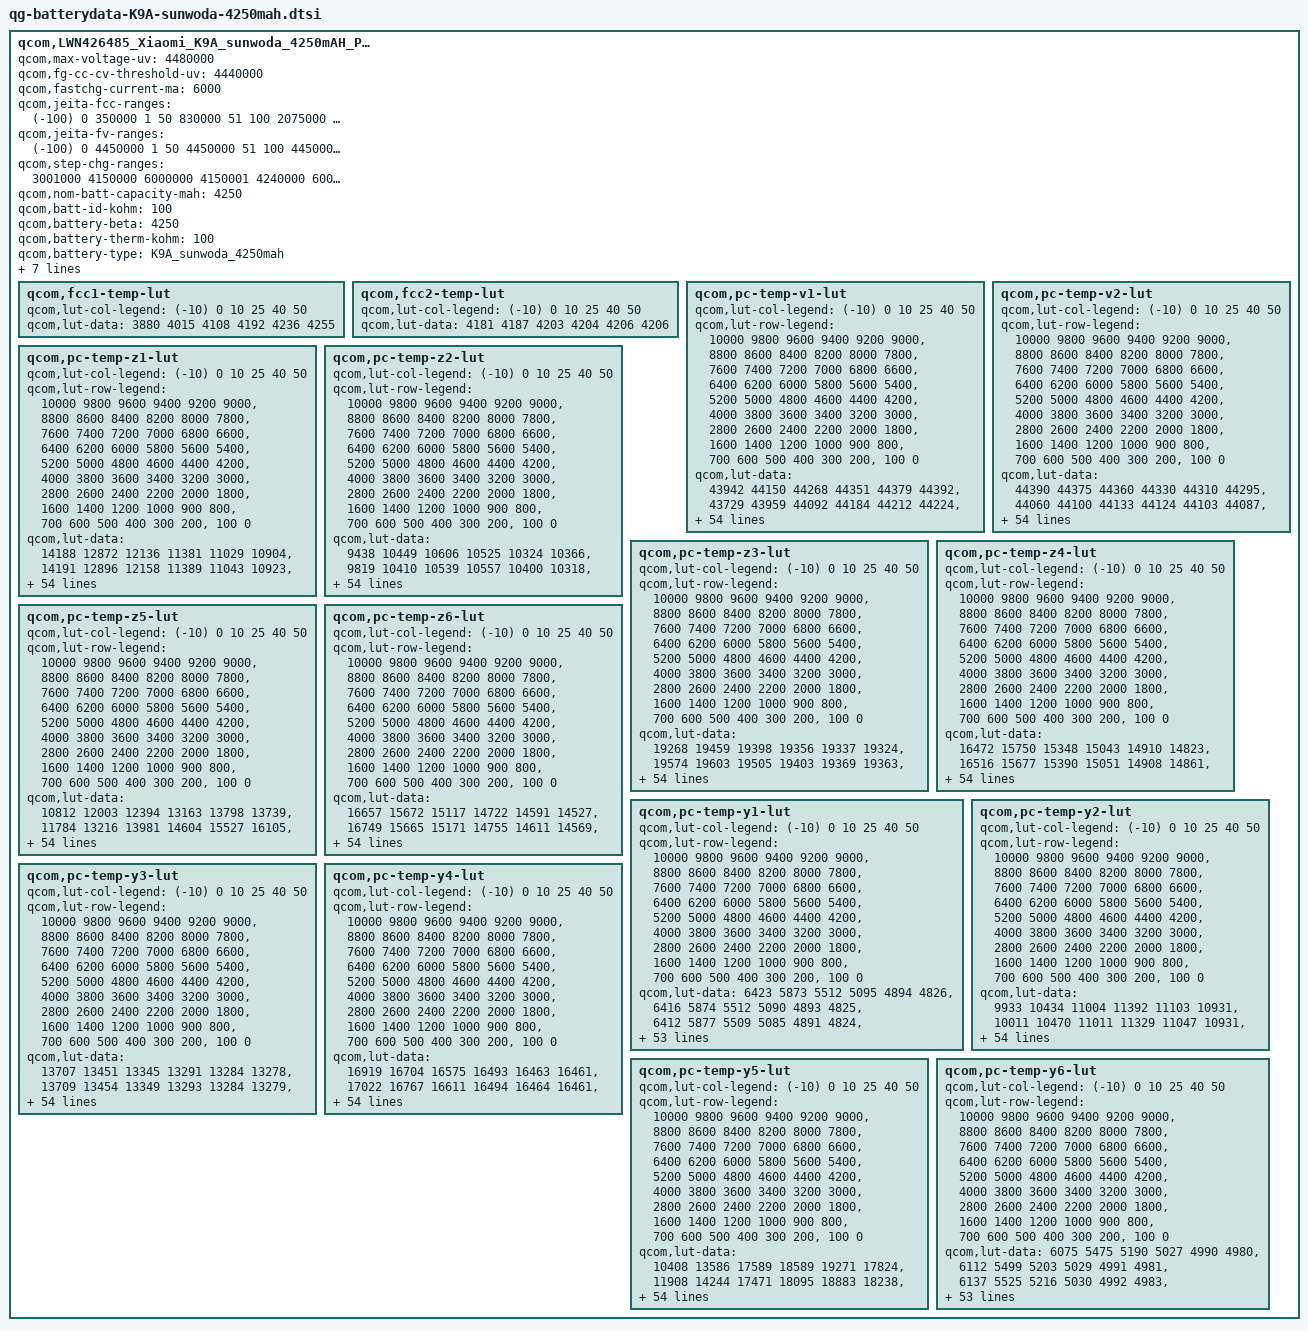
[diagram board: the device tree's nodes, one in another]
qcom,LWN426485_Xiaomi_K9A_sunwoda_4250mAH_PM7150 {
	/* LWN426485_Xiaomi_K9A_sunwoda_4250mAH_PM7150_averaged_MasterSlave_Sep23th2020 */
	qcom,max-voltage-uv = <4480000>;
	qcom,fg-cc-cv-threshold-uv = <4440000>;
	qcom,fastchg-current-ma = <6000>;
	qcom,jeita-fcc-ranges = <(-100)  0   350000
				1  50  830000
				51  100  2075000
				101 150  3320000
				151 480  6000000
				481 600  2075000>;
	qcom,jeita-fv-ranges = <(-100)  0   4450000
				1   50  4450000
				51  100  4450000
				101 150  4450000
				151 480  4480000
				481 600  4100000>;
	qcom,step-chg-ranges = <3001000  4150000  6000000
				4150001  4240000  6000000
				4240001  4350000  5400000
				4350001  4400000  5400000
				4400001  4440000  5400000
				4440001  4480000  3320000>;

	qcom,nom-batt-capacity-mah = <4250>;
	qcom,batt-id-kohm = <100>;
	qcom,battery-beta = <4250>;
	qcom,battery-therm-kohm = <100>;
	qcom,battery-type = "K9A_sunwoda_4250mah";
	qcom,qg-batt-profile-ver = <100>;
	qcom,taper-fcc;

	mi,six-pin-battery;
	mi,use-bq-pump;
	mi,step-chg-hysteresis = <5000>;
	mi-ffc-current-cfg = <350 870000 870000 (-550) (-600)>;	/* specification 100% current: 849mA */

	qcom,fcc1-temp-lut {
		qcom,lut-col-legend = <(-10) 0 10 25 40 50>;
		qcom,lut-data = <3880 4015 4108 4192 4236 4255>;
	};

	qcom,fcc2-temp-lut {
		qcom,lut-col-legend = <(-10) 0 10 25 40 50>;
		qcom,lut-data = <4181 4187 4203 4204 4206 4206>;
	};

	qcom,pc-temp-v1-lut {
		qcom,lut-col-legend = <(-10) 0 10 25 40 50>;
		qcom,lut-row-legend = <10000 9800 9600 9400 9200 9000>,
			<8800 8600 8400 8200 8000 7800>,
			<7600 7400 7200 7000 6800 6600>,
			<6400 6200 6000 5800 5600 5400>,
			<5200 5000 4800 4600 4400 4200>,
			<4000 3800 3600 3400 3200 3000>,
			<2800 2600 2400 2200 2000 1800>,
			<1600 1400 1200 1000 900 800>,
			<700 600 500 400 300 200>,
			<100 0>;
		qcom,lut-data = <43942 44150 44268 44351 44379 44392>,
			<43729 43959 44092 44184 44212 44224>,
			<43494 43756 43902 44006 44036 44051>,
			<43254 43541 43702 43817 43851 43868>,
			<43019 43311 43488 43618 43657 43674>,
			<42783 43076 43259 43405 43451 43469>,
			<42548 42838 43024 43176 43229 43250>,
			<42312 42596 42783 42939 42995 43020>,
			<42078 42357 42537 42696 42756 42783>,
			<41851 42119 42294 42448 42508 42538>,
			<41633 41884 42053 42203 42261 42291>,
			<41422 41655 41816 41962 42017 42046>,
			<41214 41430 41585 41723 41775 41802>,
			<41012 41212 41357 41487 41538 41563>,
			<40811 41003 41139 41256 41306 41331>,
			<40604 40800 40930 41033 41080 41104>,
			<40390 40593 40728 40818 40860 40883>,
			<40191 40381 40528 40610 40647 40667>,
			<40017 40176 40336 40418 40446 40463>,
			<39858 39993 40129 40232 40260 40275>,
			<39702 39827 39876 40012 40054 40074>,
			<39545 39642 39611 39721 39792 39822>,
			<39391 39392 39386 39448 39520 39551>,
			<39236 39134 39185 39264 39316 39338>,
			<39075 38961 39023 39116 39152 39165>,
			<38927 38840 38912 38985 39006 39014>,
			<38813 38745 38826 38865 38872 38878>,
			<38717 38674 38740 38756 38751 38756>,
			<38639 38617 38651 38650 38639 38644>,
			<38577 38561 38565 38547 38536 38540>,
			<38527 38503 38486 38456 38442 38445>,
			<38480 38446 38411 38377 38354 38356>,
			<38435 38393 38345 38305 38274 38274>,
			<38394 38342 38289 38240 38201 38196>,
			<38355 38295 38240 38182 38134 38123>,
			<38321 38254 38195 38126 38068 38049>,
			<38282 38216 38156 38076 38005 37972>,
			<38227 38165 38109 38024 37939 37890>,
			<38149 38083 38031 37951 37857 37797>,
			<38060 37979 37926 37851 37755 37688>,
			<37962 37862 37810 37737 37640 37569>,
			<37846 37722 37678 37611 37509 37435>,
			<37691 37566 37528 37469 37365 37290>,
			<37512 37399 37350 37300 37198 37124>,
			<37355 37297 37215 37164 37079 37013>,
			<37264 37213 37137 37085 37011 36951>,
			<37230 37182 37117 37066 36991 36935>,
			<37201 37155 37096 37047 36979 36918>,
			<37158 37116 37078 37022 36948 36882>,
			<36999 36983 36951 36924 36800 36696>,
			<36630 36611 36571 36584 36428 36323>,
			<36127 36111 36083 36113 35954 35844>,
			<35488 35473 35452 35506 35337 35219>,
			<34607 34594 34580 34673 34495 34363>,
			<33175 33168 33174 33368 33174 33011>,
			<30000 30000 30000 30000 30000 30000>;
	};

	qcom,pc-temp-v2-lut {
		qcom,lut-col-legend = <(-10) 0 10 25 40 50>;
		qcom,lut-row-legend = <10000 9800 9600 9400 9200 9000>,
			<8800 8600 8400 8200 8000 7800>,
			<7600 7400 7200 7000 6800 6600>,
			<6400 6200 6000 5800 5600 5400>,
			<5200 5000 4800 4600 4400 4200>,
			<4000 3800 3600 3400 3200 3000>,
			<2800 2600 2400 2200 2000 1800>,
			<1600 1400 1200 1000 900 800>,
			<700 600 500 400 300 200>,
			<100 0>;
		qcom,lut-data = <44390 44375 44360 44330 44310 44295>,
			<44060 44100 44133 44124 44103 44087>,
			<43758 43844 43912 43918 43896 43880>,
			<43488 43612 43699 43714 43690 43675>,
			<43253 43405 43496 43512 43487 43473>,
			<43019 43193 43286 43302 43277 43264>,
			<42762 42953 43053 43074 43050 43037>,
			<42498 42698 42809 42833 42812 42801>,
			<42260 42442 42562 42591 42572 42561>,
			<42052 42179 42313 42344 42327 42317>,
			<41839 41926 42064 42098 42082 42073>,
			<41579 41697 41819 41856 41840 41832>,
			<41298 41481 41576 41616 41600 41593>,
			<41081 41267 41340 41380 41365 41358>,
			<40941 41052 41109 41150 41137 41128>,
			<40788 40836 40887 40924 40914 40904>,
			<40492 40615 40688 40708 40697 40689>,
			<40055 40390 40499 40497 40486 40481>,
			<39696 40144 40278 40285 40281 40279>,
			<39439 39856 40001 40072 40088 40089>,
			<39213 39569 39721 39851 39886 39889>,
			<38989 39326 39477 39597 39635 39639>,
			<38772 39106 39252 39322 39353 39357>,
			<38592 38910 39058 39104 39129 39134>,
			<38442 38736 38891 38937 38961 38968>,
			<38320 38575 38741 38794 38816 38824>,
			<38234 38403 38604 38664 38685 38692>,
			<38170 38222 38479 38547 38567 38572>,
			<38112 38098 38365 38437 38458 38462>,
			<38059 38029 38263 38332 38357 38362>,
			<38008 37978 38168 38235 38265 38269>,
			<37954 37934 38070 38146 38180 38183>,
			<37896 37898 37971 38067 38103 38104>,
			<37837 37859 37891 37990 38022 38019>,
			<37779 37814 37833 37919 37935 37922>,
			<37720 37764 37783 37848 37842 37819>,
			<37653 37707 37734 37762 37742 37708>,
			<37577 37641 37689 37662 37631 37590>,
			<37494 37564 37631 37563 37525 37478>,
			<37396 37468 37541 37470 37432 37381>,
			<37289 37356 37428 37373 37337 37285>,
			<37189 37238 37301 37254 37220 37164>,
			<37095 37109 37155 37114 37083 37024>,
			<37011 37001 37031 36994 36961 36901>,
			<36938 36914 36931 36909 36873 36816>,
			<36860 36815 36858 36881 36843 36793>,
			<36813 36753 36821 36861 36832 36782>,
			<36756 36665 36777 36829 36813 36762>,
			<36675 36557 36688 36750 36761 36695>,
			<36526 36407 36503 36437 36543 36427>,
			<36243 36143 36163 35965 36114 35989>,
			<35774 35679 35613 35351 35569 35430>,
			<35096 35018 34876 34538 34860 34697>,
			<34143 34068 33875 33341 33863 33683>,
			<32437 32333 32156 31825 32358 32154>,
			<27192 27175 27324 29658 28869 28231>;
	};

	qcom,pc-temp-z1-lut {
		qcom,lut-col-legend = <(-10) 0 10 25 40 50>;
		qcom,lut-row-legend = <10000 9800 9600 9400 9200 9000>,
			<8800 8600 8400 8200 8000 7800>,
			<7600 7400 7200 7000 6800 6600>,
			<6400 6200 6000 5800 5600 5400>,
			<5200 5000 4800 4600 4400 4200>,
			<4000 3800 3600 3400 3200 3000>,
			<2800 2600 2400 2200 2000 1800>,
			<1600 1400 1200 1000 900 800>,
			<700 600 500 400 300 200>,
			<100 0>;
		qcom,lut-data = <14188 12872 12136 11381 11029 10904>,
			<14191 12896 12158 11389 11043 10923>,
			<14176 12910 12148 11392 11050 10934>,
			<14160 12910 12132 11387 11050 10936>,
			<14156 12902 12118 11377 11044 10934>,
			<14152 12891 12094 11367 11038 10931>,
			<14147 12878 12070 11355 11033 10928>,
			<14131 12861 12051 11343 11028 10924>,
			<14103 12844 12032 11333 11024 10922>,
			<14089 12823 12016 11323 11021 10919>,
			<14106 12802 12001 11318 11019 10918>,
			<14133 12785 11990 11314 11016 10916>,
			<14140 12771 11985 11312 11013 10915>,
			<14128 12757 11982 11309 11011 10914>,
			<14111 12736 11978 11307 11010 10913>,
			<14104 12713 11969 11306 11009 10913>,
			<14106 12698 11959 11305 11009 10913>,
			<14107 12686 11955 11305 11009 10914>,
			<14097 12680 11952 11306 11010 10914>,
			<14082 12680 11951 11307 11010 10915>,
			<14079 12680 11952 11308 11010 10916>,
			<14076 12681 11954 11309 11010 10917>,
			<14072 12682 11956 11310 11011 10917>,
			<14074 12684 11960 11312 11012 10918>,
			<14099 12688 11963 11316 11014 10920>,
			<14127 12697 11966 11321 11017 10922>,
			<14134 12706 11969 11325 11020 10924>,
			<14121 12708 11972 11331 11023 10927>,
			<14110 12708 11978 11335 11026 10930>,
			<14105 12708 11983 11340 11029 10933>,
			<14099 12708 11984 11344 11031 10935>,
			<14099 12709 11984 11348 11035 10938>,
			<14100 12714 11985 11352 11038 10940>,
			<14099 12724 11994 11356 11042 10943>,
			<14097 12731 12006 11360 11045 10946>,
			<14093 12733 12013 11365 11049 10950>,
			<14087 12730 12018 11370 11052 10953>,
			<14080 12731 12022 11376 11056 10956>,
			<14071 12739 12029 11383 11059 10958>,
			<14067 12750 12041 11391 11063 10961>,
			<14067 12764 12049 11399 11066 10964>,
			<14067 12784 12060 11405 11070 10967>,
			<14075 12792 12069 11411 11073 10969>,
			<14085 12794 12077 11421 11076 10970>,
			<14057 12817 12089 11434 11081 10973>,
			<14100 12778 12085 11445 11084 10975>,
			<14047 12790 12089 11442 11082 10975>,
			<14105 12787 12081 11444 11084 10976>,
			<14140 12786 12081 11448 11085 10977>,
			<14142 12817 12096 11461 11091 10982>,
			<14115 12800 12120 11469 11096 10985>,
			<14104 12831 12124 11478 11103 10990>,
			<14143 12849 12145 11494 11112 10998>,
			<14151 12883 12191 11506 11122 11009>,
			<14151 12883 12191 11506 11122 11009>,
			<14151 12883 12191 11506 11122 11009>;
	};

	qcom,pc-temp-z2-lut {
		qcom,lut-col-legend = <(-10) 0 10 25 40 50>;
		qcom,lut-row-legend = <10000 9800 9600 9400 9200 9000>,
			<8800 8600 8400 8200 8000 7800>,
			<7600 7400 7200 7000 6800 6600>,
			<6400 6200 6000 5800 5600 5400>,
			<5200 5000 4800 4600 4400 4200>,
			<4000 3800 3600 3400 3200 3000>,
			<2800 2600 2400 2200 2000 1800>,
			<1600 1400 1200 1000 900 800>,
			<700 600 500 400 300 200>,
			<100 0>;
		qcom,lut-data = <9438 10449 10606 10525 10324 10366>,
			<9819 10410 10539 10557 10400 10318>,
			<10009 10371 10502 10567 10444 10314>,
			<10182 10331 10462 10554 10445 10318>,
			<10179 10284 10422 10525 10425 10348>,
			<10152 10244 10379 10490 10403 10364>,
			<10131 10216 10343 10438 10359 10316>,
			<10119 10194 10314 10402 10311 10235>,
			<10109 10183 10292 10386 10297 10193>,
			<10106 10175 10286 10376 10294 10170>,
			<10133 10171 10287 10378 10294 10151>,
			<10176 10175 10291 10399 10285 10127>,
			<10192 10190 10309 10422 10269 10104>,
			<10196 10211 10352 10436 10249 10102>,
			<10197 10242 10385 10449 10206 10121>,
			<10191 10280 10403 10460 10183 10138>,
			<10173 10314 10418 10469 10193 10142>,
			<10160 10345 10437 10478 10209 10145>,
			<10169 10371 10458 10487 10222 10151>,
			<10191 10394 10469 10498 10233 10172>,
			<10200 10415 10465 10516 10252 10207>,
			<10191 10424 10458 10571 10383 10313>,
			<10176 10403 10446 10616 10550 10475>,
			<10168 10374 10420 10602 10574 10568>,
			<10164 10367 10402 10563 10540 10629>,
			<10162 10369 10420 10551 10520 10657>,
			<10164 10371 10461 10604 10511 10553>,
			<10175 10377 10481 10660 10489 10343>,
			<10189 10387 10487 10645 10444 10206>,
			<10201 10398 10490 10584 10354 10102>,
			<10214 10408 10486 10533 10306 10051>,
			<10228 10418 10470 10494 10307 10056>,
			<10242 10427 10462 10468 10310 10068>,
			<10256 10435 10465 10473 10322 10089>,
			<10267 10443 10470 10503 10363 10148>,
			<10276 10452 10477 10536 10413 10220>,
			<10286 10463 10488 10567 10463 10286>,
			<10303 10477 10503 10600 10518 10359>,
			<10327 10501 10528 10636 10576 10451>,
			<10341 10530 10561 10676 10643 10582>,
			<9978 10554 10583 10699 10676 10655>,
			<9464 10577 10594 10705 10668 10623>,
			<9460 10619 10612 10708 10657 10583>,
			<9506 10691 10653 10712 10653 10577>,
			<9581 10717 10902 10761 10555 10481>,
			<9534 10603 10936 10797 10473 10339>,
			<9570 10564 10949 10753 10438 10345>,
			<9532 10556 10997 10733 10467 10363>,
			<9516 10533 11352 10741 10536 10486>,
			<9475 10473 11393 10841 10523 10418>,
			<9395 10391 11249 10742 10285 10162>,
			<9331 10273 11198 10668 10236 10117>,
			<9273 10127 11042 10671 10183 10070>,
			<9190 9930 10881 10662 10136 10000>,
			<9190 9930 10881 10662 10136 10000>,
			<9190 9930 10881 10662 10136 10000>;
	};

	qcom,pc-temp-z3-lut {
		qcom,lut-col-legend = <(-10) 0 10 25 40 50>;
		qcom,lut-row-legend = <10000 9800 9600 9400 9200 9000>,
			<8800 8600 8400 8200 8000 7800>,
			<7600 7400 7200 7000 6800 6600>,
			<6400 6200 6000 5800 5600 5400>,
			<5200 5000 4800 4600 4400 4200>,
			<4000 3800 3600 3400 3200 3000>,
			<2800 2600 2400 2200 2000 1800>,
			<1600 1400 1200 1000 900 800>,
			<700 600 500 400 300 200>,
			<100 0>;
		qcom,lut-data = <19268 19459 19398 19356 19337 19324>,
			<19574 19603 19505 19403 19369 19363>,
			<19819 19712 19561 19437 19393 19373>,
			<20035 19774 19599 19461 19408 19385>,
			<20104 19817 19622 19478 19419 19399>,
			<20142 19844 19639 19487 19424 19407>,
			<20175 19860 19649 19492 19427 19409>,
			<20217 19872 19654 19495 19428 19409>,
			<20260 19880 19657 19494 19427 19408>,
			<20277 19886 19657 19491 19422 19403>,
			<20243 19891 19654 19486 19417 19398>,
			<20188 19892 19649 19472 19411 19395>,
			<20169 19892 19639 19459 19405 19393>,
			<20166 19891 19622 19455 19399 19390>,
			<20165 19882 19609 19453 19392 19384>,
			<20178 19867 19600 19450 19386 19378>,
			<20220 19854 19593 19445 19383 19375>,
			<20250 19845 19585 19441 19381 19373>,
			<20230 19836 19575 19436 19378 19370>,
			<20185 19826 19571 19431 19374 19365>,
			<20164 19814 19597 19432 19373 19362>,
			<20179 19810 19638 19451 19380 19364>,
			<20203 19827 19644 19468 19390 19371>,
			<20214 19853 19622 19456 19388 19381>,
			<20218 19858 19598 19424 19375 19401>,
			<20218 19848 19582 19413 19368 19415>,
			<20214 19836 19569 19418 19394 19419>,
			<20204 19824 19566 19427 19430 19421>,
			<20192 19810 19581 19445 19435 19419>,
			<20172 19801 19598 19473 19428 19408>,
			<20145 19796 19607 19484 19421 19396>,
			<20123 19792 19613 19478 19414 19388>,
			<20107 19788 19615 19469 19406 19381>,
			<20094 19785 19609 19461 19398 19373>,
			<20080 19780 19600 19452 19388 19363>,
			<20069 19775 19594 19445 19381 19358>,
			<20056 19767 19589 19440 19377 19358>,
			<20040 19758 19583 19435 19374 19359>,
			<20022 19747 19577 19431 19373 19360>,
			<19991 19735 19570 19429 19372 19366>,
			<19690 19723 19562 19427 19372 19371>,
			<19297 19711 19554 19426 19378 19375>,
			<19270 19692 19545 19424 19385 19378>,
			<19269 19655 19532 19421 19386 19380>,
			<19266 19367 19478 19405 19372 19370>,
			<19267 19321 19462 19391 19353 19350>,
			<19266 19310 19451 19383 19352 19338>,
			<19267 19305 19431 19384 19339 19335>,
			<19267 19303 19315 19378 19334 19327>,
			<19269 19304 19323 19375 19345 19343>,
			<19272 19307 19366 19390 19374 19364>,
			<19275 19310 19311 19395 19364 19359>,
			<19279 19312 19297 19364 19364 19359>,
			<19292 19315 19300 19339 19364 19364>,
			<19292 19315 19300 19339 19364 19364>,
			<19292 19315 19300 19339 19364 19364>;
	};

	qcom,pc-temp-z4-lut {
		qcom,lut-col-legend = <(-10) 0 10 25 40 50>;
		qcom,lut-row-legend = <10000 9800 9600 9400 9200 9000>,
			<8800 8600 8400 8200 8000 7800>,
			<7600 7400 7200 7000 6800 6600>,
			<6400 6200 6000 5800 5600 5400>,
			<5200 5000 4800 4600 4400 4200>,
			<4000 3800 3600 3400 3200 3000>,
			<2800 2600 2400 2200 2000 1800>,
			<1600 1400 1200 1000 900 800>,
			<700 600 500 400 300 200>,
			<100 0>;
		qcom,lut-data = <16472 15750 15348 15043 14910 14823>,
			<16516 15677 15390 15051 14908 14861>,
			<16324 15594 15336 15052 14902 14855>,
			<16100 15496 15241 15017 14888 14845>,
			<15943 15378 15164 14956 14856 14821>,
			<15814 15273 15092 14913 14826 14794>,
			<15693 15193 15029 14880 14803 14775>,
			<15565 15124 14978 14850 14784 14758>,
			<15440 15068 14935 14818 14767 14746>,
			<15356 15021 14898 14790 14751 14737>,
			<15312 14981 14866 14779 14742 14730>,
			<15280 14944 14840 14774 14737 14724>,
			<15256 14910 14821 14769 14733 14719>,
			<15235 14880 14806 14760 14730 14714>,
			<15219 14853 14797 14749 14727 14711>,
			<15211 14830 14790 14740 14722 14707>,
			<15205 14822 14786 14733 14715 14702>,
			<15204 14821 14787 14728 14707 14695>,
			<15223 14820 14790 14724 14702 14690>,
			<15259 14820 14795 14721 14697 14686>,
			<15274 14820 14806 14724 14695 14685>,
			<15248 14821 14824 14770 14733 14718>,
			<15211 14862 14854 14827 14791 14777>,
			<15206 14924 14914 14865 14818 14788>,
			<15253 14943 14955 14896 14834 14768>,
			<15300 14948 14953 14904 14840 14746>,
			<15304 14950 14942 14887 14803 14729>,
			<15298 14943 14926 14859 14747 14715>,
			<15289 14921 14893 14826 14727 14709>,
			<15274 14899 14857 14783 14719 14707>,
			<15250 14879 14834 14759 14713 14705>,
			<15228 14861 14815 14750 14707 14700>,
			<15209 14846 14805 14745 14703 14694>,
			<15190 14835 14801 14743 14702 14693>,
			<15172 14825 14798 14742 14704 14693>,
			<15154 14815 14795 14742 14705 14694>,
			<15137 14806 14791 14743 14707 14695>,
			<15119 14801 14789 14744 14709 14697>,
			<15100 14798 14791 14749 14714 14699>,
			<15090 14795 14794 14758 14723 14701>,
			<15353 14788 14793 14764 14728 14702>,
			<15726 14774 14777 14754 14718 14698>,
			<15731 14760 14760 14741 14707 14692>,
			<15665 14749 14749 14735 14707 14695>,
			<15496 14911 14714 14715 14699 14687>,
			<15470 14937 14694 14691 14685 14673>,
			<15458 14942 14689 14682 14674 14669>,
			<15446 14937 14700 14661 14663 14650>,
			<15429 14933 14821 14652 14649 14638>,
			<15438 14934 14814 14664 14654 14653>,
			<15464 14947 14781 14678 14657 14657>,
			<15482 14953 14852 14676 14668 14664>,
			<15507 14960 14872 14714 14669 14665>,
			<15547 14969 14872 14742 14669 14658>,
			<15547 14969 14872 14742 14669 14658>,
			<15547 14969 14872 14742 14669 14658>;
	};

	qcom,pc-temp-z5-lut {
		qcom,lut-col-legend = <(-10) 0 10 25 40 50>;
		qcom,lut-row-legend = <10000 9800 9600 9400 9200 9000>,
			<8800 8600 8400 8200 8000 7800>,
			<7600 7400 7200 7000 6800 6600>,
			<6400 6200 6000 5800 5600 5400>,
			<5200 5000 4800 4600 4400 4200>,
			<4000 3800 3600 3400 3200 3000>,
			<2800 2600 2400 2200 2000 1800>,
			<1600 1400 1200 1000 900 800>,
			<700 600 500 400 300 200>,
			<100 0>;
		qcom,lut-data = <10812 12003 12394 13163 13798 13739>,
			<11784 13216 13981 14604 15527 16105>,
			<12671 14251 15019 15674 16833 16883>,
			<13470 15061 15830 16421 17594 17814>,
			<13868 15718 16475 16982 18126 19080>,
			<14140 16313 16974 17331 18457 19945>,
			<14466 16857 17476 17550 18625 20184>,
			<15202 17372 18064 17818 18767 20329>,
			<16298 17978 18701 18497 19077 20464>,
			<16865 18693 19411 19287 19635 20637>,
			<16888 19535 20261 19395 19990 20861>,
			<16880 20614 21092 19006 19849 21298>,
			<16934 22065 21809 18716 19570 21822>,
			<17153 23562 22462 19072 19449 21894>,
			<17527 24921 22849 19886 19155 21537>,
			<18459 26346 23062 20547 19101 21268>,
			<20693 28137 23194 21085 19640 21793>,
			<22228 30898 23170 21584 20447 22894>,
			<21284 32890 22938 21974 21102 23637>,
			<19100 32680 22839 22339 21692 24259>,
			<18095 31675 31969 23413 22288 24582>,
			<19147 31198 46389 28690 23078 24246>,
			<20949 37199 48163 33302 23744 23459>,
			<22229 45846 38146 29993 22780 22591>,
			<23393 47285 28385 21211 18218 21285>,
			<24181 43197 24494 17586 15568 20498>,
			<24204 38459 21796 17292 17687 21667>,
			<23998 35323 21172 17159 21052 23723>,
			<23735 32594 22410 18386 22609 24143>,
			<23076 31636 24480 22311 23415 23600>,
			<22047 32216 27186 25281 24187 23203>,
			<21566 33316 31001 26884 25319 23516>,
			<21482 34582 33668 28073 26290 24042>,
			<21431 36447 35171 28963 26403 24106>,
			<21390 38133 36143 29720 26242 23927>,
			<21350 39126 36257 30003 26129 23810>,
			<21303 39895 36112 29847 26062 24765>,
			<21230 40573 35887 29491 25919 26359>,
			<21090 41336 35271 28606 25369 26683>,
			<20837 41899 34145 26492 23493 26572>,
			<16853 41928 33119 25224 22360 26494>,
			<11426 41662 32173 25169 24016 27924>,
			<11086 40822 31345 25101 25610 29481>,
			<11096 36892 30435 24332 25319 29232>,
			<11249 15275 30456 24070 22800 26332>,
			<11196 12751 29819 24258 19780 20930>,
			<11174 12464 26366 23018 20681 18679>,
			<11172 12367 25442 26041 19952 21384>,
			<11172 12354 12863 27041 22577 24094>,
			<11188 12437 13363 22848 23095 28005>,
			<11181 12433 15706 20515 24748 25249>,
			<11119 12330 12553 20408 19547 20586>,
			<11061 12207 12104 16049 18661 19126>,
			<10962 12040 12054 13488 17586 18933>,
			<10962 12040 12054 13488 17586 18933>,
			<10962 12040 12054 13488 17586 18933>;
	};

	qcom,pc-temp-z6-lut {
		qcom,lut-col-legend = <(-10) 0 10 25 40 50>;
		qcom,lut-row-legend = <10000 9800 9600 9400 9200 9000>,
			<8800 8600 8400 8200 8000 7800>,
			<7600 7400 7200 7000 6800 6600>,
			<6400 6200 6000 5800 5600 5400>,
			<5200 5000 4800 4600 4400 4200>,
			<4000 3800 3600 3400 3200 3000>,
			<2800 2600 2400 2200 2000 1800>,
			<1600 1400 1200 1000 900 800>,
			<700 600 500 400 300 200>,
			<100 0>;
		qcom,lut-data = <16657 15672 15117 14722 14591 14527>,
			<16749 15665 15171 14755 14611 14569>,
			<16719 15650 15155 14768 14622 14574>,
			<16668 15624 15126 14760 14621 14574>,
			<16613 15566 15096 14744 14614 14571>,
			<16538 15507 15062 14730 14605 14566>,
			<16464 15463 15029 14717 14597 14561>,
			<16402 15423 15001 14703 14589 14553>,
			<16344 15390 14975 14689 14581 14546>,
			<16290 15363 14953 14674 14571 14539>,
			<16236 15339 14933 14662 14563 14533>,
			<16188 15316 14914 14653 14557 14529>,
			<16165 15295 14896 14644 14552 14525>,
			<16153 15273 14879 14637 14547 14521>,
			<16146 15247 14867 14631 14541 14516>,
			<16149 15222 14859 14625 14536 14511>,
			<16162 15207 14852 14619 14531 14506>,
			<16172 15198 14848 14614 14526 14502>,
			<16171 15191 14844 14610 14521 14498>,
			<16168 15186 14842 14606 14517 14493>,
			<16165 15181 14858 14608 14515 14491>,
			<16164 15180 14889 14642 14537 14507>,
			<16164 15208 14907 14674 14568 14536>,
			<16169 15249 14920 14677 14575 14545>,
			<16195 15258 14927 14678 14577 14547>,
			<16219 15257 14923 14678 14578 14548>,
			<16221 15254 14912 14674 14576 14546>,
			<16218 15246 14903 14668 14571 14541>,
			<16213 15231 14897 14664 14566 14535>,
			<16200 15217 14892 14661 14560 14529>,
			<16179 15207 14888 14657 14554 14523>,
			<16160 15198 14885 14651 14548 14517>,
			<16145 15192 14882 14645 14543 14511>,
			<16133 15188 14877 14640 14538 14506>,
			<16122 15184 14873 14636 14534 14501>,
			<16113 15178 14870 14633 14531 14498>,
			<16105 15172 14868 14631 14530 14499>,
			<16099 15170 14867 14630 14529 14500>,
			<16095 15169 14868 14631 14530 14502>,
			<16088 15169 14868 14635 14534 14506>,
			<16067 15167 14868 14637 14536 14509>,
			<16042 15162 14861 14633 14535 14509>,
			<16039 15156 14853 14629 14535 14509>,
			<16036 15143 14848 14626 14535 14511>,
			<15985 15080 14815 14612 14526 14503>,
			<15979 15066 14801 14596 14510 14487>,
			<15973 15063 14794 14588 14504 14478>,
			<15974 15060 14789 14580 14493 14468>,
			<15976 15060 14784 14574 14484 14458>,
			<15993 15070 14792 14579 14493 14474>,
			<16020 15082 14804 14595 14512 14490>,
			<16042 15094 14810 14600 14513 14492>,
			<16080 15108 14819 14604 14516 14495>,
			<16131 15131 14831 14608 14520 14498>,
			<16131 15131 14831 14608 14520 14498>,
			<16131 15131 14831 14608 14520 14498>;
	};

	qcom,pc-temp-y1-lut {
		qcom,lut-col-legend = <(-10) 0 10 25 40 50>;
		qcom,lut-row-legend = <10000 9800 9600 9400 9200 9000>,
			<8800 8600 8400 8200 8000 7800>,
			<7600 7400 7200 7000 6800 6600>,
			<6400 6200 6000 5800 5600 5400>,
			<5200 5000 4800 4600 4400 4200>,
			<4000 3800 3600 3400 3200 3000>,
			<2800 2600 2400 2200 2000 1800>,
			<1600 1400 1200 1000 900 800>,
			<700 600 500 400 300 200>,
			<100 0>;
		qcom,lut-data = <6423 5873 5512 5095 4894 4826>,
			<6416 5874 5512 5090 4893 4825>,
			<6412 5877 5509 5085 4891 4824>,
			<6409 5880 5505 5080 4889 4823>,
			<6409 5883 5502 5075 4887 4822>,
			<6409 5884 5499 5071 4885 4821>,
			<6412 5884 5497 5067 4883 4820>,
			<6416 5884 5494 5063 4881 4819>,
			<6420 5883 5492 5060 4879 4817>,
			<6436 5878 5489 5058 4877 4816>,
			<6450 5873 5484 5056 4876 4815>,
			<6453 5874 5480 5054 4875 4815>,
			<6455 5877 5474 5050 4873 4815>,
			<6456 5877 5471 5049 4872 4815>,
			<6449 5878 5470 5048 4871 4814>,
			<6443 5879 5468 5047 4870 4813>,
			<6447 5881 5463 5047 4870 4813>,
			<6452 5884 5456 5046 4870 4812>,
			<6454 5887 5454 5045 4870 4812>,
			<6451 5894 5454 5045 4870 4813>,
			<6447 5902 5455 5046 4871 4813>,
			<6443 5904 5456 5047 4871 4813>,
			<6434 5900 5459 5049 4872 4814>,
			<6430 5899 5461 5051 4872 4815>,
			<6439 5903 5467 5053 4874 4816>,
			<6449 5907 5472 5055 4876 4817>,
			<6448 5902 5471 5057 4877 4818>,
			<6434 5882 5468 5060 4878 4819>,
			<6429 5872 5467 5063 4879 4820>,
			<6437 5883 5474 5065 4881 4821>,
			<6446 5896 5482 5067 4883 4823>,
			<6448 5900 5486 5070 4885 4824>,
			<6439 5903 5491 5073 4887 4826>,
			<6430 5903 5494 5076 4890 4828>,
			<6414 5890 5495 5080 4892 4829>,
			<6388 5874 5497 5085 4893 4831>,
			<6384 5872 5500 5089 4895 4832>,
			<6395 5879 5506 5092 4897 4834>,
			<6403 5885 5514 5095 4899 4836>,
			<6395 5881 5531 5098 4900 4838>,
			<6379 5873 5549 5101 4901 4839>,
			<6375 5872 5551 5107 4903 4841>,
			<6388 5884 5546 5114 4906 4842>,
			<6390 5882 5545 5121 4909 4844>,
			<6375 5853 5548 5128 4913 4847>,
			<6387 5894 5554 5134 4915 4848>,
			<6394 5883 5540 5130 4914 4848>,
			<6427 5893 5552 5129 4914 4847>,
			<6463 5890 5539 5126 4913 4848>,
			<6428 5880 5558 5129 4913 4849>,
			<6403 5886 5543 5135 4916 4852>,
			<6458 5882 5559 5151 4922 4855>,
			<6571 5900 5579 5165 4927 4860>,
			<6684 5949 5579 5186 4935 4868>,
			<6684 5949 5579 5186 4935 4868>,
			<6684 5949 5579 5186 4935 4868>;
	};

	qcom,pc-temp-y2-lut {
		qcom,lut-col-legend = <(-10) 0 10 25 40 50>;
		qcom,lut-row-legend = <10000 9800 9600 9400 9200 9000>,
			<8800 8600 8400 8200 8000 7800>,
			<7600 7400 7200 7000 6800 6600>,
			<6400 6200 6000 5800 5600 5400>,
			<5200 5000 4800 4600 4400 4200>,
			<4000 3800 3600 3400 3200 3000>,
			<2800 2600 2400 2200 2000 1800>,
			<1600 1400 1200 1000 900 800>,
			<700 600 500 400 300 200>,
			<100 0>;
		qcom,lut-data = <9933 10434 11004 11392 11103 10931>,
			<10011 10470 11011 11329 11047 10931>,
			<10093 10536 11014 11262 10992 10918>,
			<10172 10612 11013 11197 10941 10894>,
			<10239 10675 11010 11142 10896 10864>,
			<10287 10705 11005 11102 10860 10833>,
			<10310 10706 10991 11072 10831 10790>,
			<10328 10704 10971 11050 10807 10740>,
			<10371 10706 10962 11043 10794 10714>,
			<10502 10716 10958 11041 10785 10699>,
			<10602 10728 10956 11041 10784 10688>,
			<10590 10768 10971 11051 10804 10685>,
			<10558 10841 11008 11070 10840 10687>,
			<10551 10867 11038 11084 10869 10689>,
			<10609 10837 11060 11108 10893 10697>,
			<10678 10812 11085 11143 10916 10708>,
			<10625 10888 11136 11200 10938 10731>,
			<10412 11063 11201 11285 10961 10772>,
			<10293 11128 11226 11361 11008 10832>,
			<10025 11093 11233 11440 11155 10952>,
			<9741 11056 11236 11489 11275 11044>,
			<9702 11066 11237 11457 11246 11039>,
			<9693 11103 11240 11371 11162 11018>,
			<9686 11118 11244 11335 11124 11009>,
			<9681 11071 11266 11335 11126 10997>,
			<9676 11009 11293 11342 11142 10988>,
			<9673 10989 11310 11361 11178 11003>,
			<9671 10974 11325 11400 11239 11048>,
			<9670 10957 11333 11433 11292 11104>,
			<9669 10919 11337 11455 11349 11220>,
			<9668 10852 11339 11476 11400 11335>,
			<9666 10721 11330 11503 11432 11373>,
			<9665 10425 11299 11535 11468 11392>,
			<9664 10201 11270 11552 11482 11398>,
			<9664 9997 11247 11558 11481 11427>,
			<9663 9763 11220 11562 11476 11451>,
			<9663 9701 11184 11540 11432 11396>,
			<9663 9683 11133 11456 11294 11258>,
			<9662 9674 11068 11399 11208 11163>,
			<9662 9669 10975 11386 11190 11124>,
			<9662 9666 10863 11376 11185 11096>,
			<9661 9663 10755 11354 11173 11075>,
			<9661 9662 10646 11309 11121 11040>,
			<9660 9661 10533 11221 11047 10974>,
			<9659 9660 10428 11095 10926 10853>,
			<9659 9659 10366 11039 10846 10741>,
			<9658 9659 10430 11074 10917 10749>,
			<9658 9659 10425 11074 10934 10843>,
			<9657 9658 10406 11084 10977 10796>,
			<9655 9657 10402 11037 10896 10787>,
			<9654 9657 10357 10983 10805 10710>,
			<9651 9655 10033 10897 10770 10655>,
			<9649 9653 9701 10842 10730 10582>,
			<9648 9650 9668 10779 10651 10472>,
			<9648 9650 9668 10779 10651 10472>,
			<9648 9650 9668 10779 10651 10472>;
	};

	qcom,pc-temp-y3-lut {
		qcom,lut-col-legend = <(-10) 0 10 25 40 50>;
		qcom,lut-row-legend = <10000 9800 9600 9400 9200 9000>,
			<8800 8600 8400 8200 8000 7800>,
			<7600 7400 7200 7000 6800 6600>,
			<6400 6200 6000 5800 5600 5400>,
			<5200 5000 4800 4600 4400 4200>,
			<4000 3800 3600 3400 3200 3000>,
			<2800 2600 2400 2200 2000 1800>,
			<1600 1400 1200 1000 900 800>,
			<700 600 500 400 300 200>,
			<100 0>;
		qcom,lut-data = <13707 13451 13345 13291 13284 13278>,
			<13709 13454 13349 13293 13284 13279>,
			<13709 13460 13353 13295 13284 13280>,
			<13706 13467 13357 13297 13284 13281>,
			<13702 13473 13361 13299 13285 13282>,
			<13696 13476 13364 13300 13286 13283>,
			<13686 13476 13366 13301 13287 13284>,
			<13674 13476 13368 13302 13288 13285>,
			<13669 13476 13370 13303 13290 13286>,
			<13667 13472 13372 13304 13291 13287>,
			<13665 13469 13373 13306 13292 13288>,
			<13624 13477 13372 13307 13293 13289>,
			<13540 13495 13369 13310 13293 13290>,
			<13513 13496 13366 13311 13295 13291>,
			<13523 13450 13363 13312 13298 13291>,
			<13533 13407 13360 13313 13301 13291>,
			<13524 13414 13358 13312 13300 13293>,
			<13497 13437 13355 13311 13299 13296>,
			<13483 13445 13352 13311 13298 13297>,
			<13481 13429 13348 13312 13300 13297>,
			<13481 13407 13345 13313 13301 13297>,
			<13482 13396 13341 13310 13298 13293>,
			<13482 13389 13337 13301 13289 13285>,
			<13482 13381 13334 13296 13285 13281>,
			<13474 13375 13333 13294 13284 13281>,
			<13466 13368 13331 13292 13283 13281>,
			<13470 13358 13330 13293 13283 13281>,
			<13493 13346 13329 13294 13283 13281>,
			<13523 13340 13327 13294 13283 13281>,
			<13557 13339 13326 13294 13282 13283>,
			<13597 13341 13326 13293 13282 13284>,
			<13638 13346 13325 13293 13282 13284>,
			<13680 13359 13325 13293 13283 13282>,
			<13724 13376 13325 13294 13284 13282>,
			<13772 13396 13325 13295 13284 13282>,
			<13821 13420 13325 13296 13284 13283>,
			<13866 13451 13327 13296 13283 13283>,
			<13909 13490 13332 13294 13283 13281>,
			<13948 13537 13336 13293 13282 13280>,
			<13980 13591 13339 13293 13283 13281>,
			<14008 13653 13342 13293 13285 13283>,
			<14036 13713 13345 13294 13285 13283>,
			<14061 13773 13350 13294 13284 13282>,
			<14099 13839 13357 13295 13284 13281>,
			<14161 13911 13368 13299 13286 13281>,
			<14245 13963 13384 13310 13289 13288>,
			<14228 13888 13379 13310 13295 13290>,
			<14252 13890 13392 13314 13297 13293>,
			<14376 13955 13402 13318 13298 13291>,
			<14534 14022 13411 13309 13293 13286>,
			<14834 14100 13419 13311 13290 13287>,
			<15653 14244 13433 13314 13291 13288>,
			<17710 14636 13525 13325 13299 13293>,
			<22277 15774 13783 13339 13305 13302>,
			<22277 15774 13783 13339 13305 13302>,
			<22277 15774 13783 13339 13305 13302>;
	};

	qcom,pc-temp-y4-lut {
		qcom,lut-col-legend = <(-10) 0 10 25 40 50>;
		qcom,lut-row-legend = <10000 9800 9600 9400 9200 9000>,
			<8800 8600 8400 8200 8000 7800>,
			<7600 7400 7200 7000 6800 6600>,
			<6400 6200 6000 5800 5600 5400>,
			<5200 5000 4800 4600 4400 4200>,
			<4000 3800 3600 3400 3200 3000>,
			<2800 2600 2400 2200 2000 1800>,
			<1600 1400 1200 1000 900 800>,
			<700 600 500 400 300 200>,
			<100 0>;
		qcom,lut-data = <16919 16704 16575 16493 16463 16461>,
			<17022 16767 16611 16494 16464 16461>,
			<17145 16866 16658 16496 16466 16462>,
			<17264 16974 16705 16497 16467 16462>,
			<17356 17062 16742 16499 16469 16462>,
			<17395 17102 16757 16501 16470 16462>,
			<17383 17097 16753 16503 16470 16463>,
			<17356 17086 16744 16505 16470 16463>,
			<17334 17076 16736 16508 16471 16463>,
			<17314 17068 16729 16513 16473 16464>,
			<17303 17059 16724 16517 16475 16465>,
			<17353 17048 16728 16521 16479 16467>,
			<17464 17035 16739 16526 16484 16470>,
			<17504 17042 16752 16532 16487 16474>,
			<17498 17153 16770 16542 16489 16479>,
			<17482 17257 16793 16555 16492 16484>,
			<17391 17230 16828 16576 16501 16489>,
			<17177 17132 16869 16603 16517 16494>,
			<17050 17043 16875 16615 16536 16503>,
			<17008 16963 16810 16620 16562 16529>,
			<16974 16892 16728 16622 16580 16550>,
			<16914 16841 16680 16595 16559 16534>,
			<16833 16800 16640 16527 16506 16494>,
			<16796 16764 16617 16501 16481 16474>,
			<16791 16735 16604 16500 16476 16468>,
			<16790 16706 16596 16499 16473 16465>,
			<16794 16665 16591 16500 16474 16466>,
			<16802 16612 16588 16505 16480 16470>,
			<16808 16588 16586 16511 16486 16474>,
			<16807 16599 16586 16517 16495 16478>,
			<16807 16618 16585 16525 16505 16484>,
			<16810 16635 16576 16533 16514 16494>,
			<16823 16657 16550 16543 16524 16508>,
			<16834 16679 16539 16546 16528 16513>,
			<16838 16709 16544 16546 16524 16509>,
			<16841 16740 16555 16546 16517 16502>,
			<16841 16759 16569 16538 16506 16494>,
			<16840 16774 16591 16511 16487 16483>,
			<16838 16782 16608 16496 16477 16478>,
			<16832 16780 16620 16497 16475 16477>,
			<16822 16775 16628 16497 16474 16476>,
			<16820 16769 16631 16497 16472 16473>,
			<16827 16759 16631 16496 16468 16464>,
			<16838 16759 16634 16495 16461 16454>,
			<16862 16785 16644 16495 16454 16448>,
			<16893 16832 16674 16517 16483 16486>,
			<16867 16812 16660 16522 16499 16514>,
			<16854 16826 16695 16549 16531 16544>,
			<16873 16869 16736 16571 16556 16559>,
			<16878 16904 16774 16515 16509 16487>,
			<16874 16911 16782 16505 16471 16466>,
			<16973 16886 16772 16516 16474 16469>,
			<17451 16900 16837 16543 16476 16469>,
			<19444 17246 16942 16630 16499 16505>,
			<19444 17246 16942 16630 16499 16505>,
			<19444 17246 16942 16630 16499 16505>;
	};

	qcom,pc-temp-y5-lut {
		qcom,lut-col-legend = <(-10) 0 10 25 40 50>;
		qcom,lut-row-legend = <10000 9800 9600 9400 9200 9000>,
			<8800 8600 8400 8200 8000 7800>,
			<7600 7400 7200 7000 6800 6600>,
			<6400 6200 6000 5800 5600 5400>,
			<5200 5000 4800 4600 4400 4200>,
			<4000 3800 3600 3400 3200 3000>,
			<2800 2600 2400 2200 2000 1800>,
			<1600 1400 1200 1000 900 800>,
			<700 600 500 400 300 200>,
			<100 0>;
		qcom,lut-data = <10408 13586 17589 18589 19271 17824>,
			<11908 14244 17471 18095 18883 18238>,
			<13443 15018 17327 17617 18220 18453>,
			<14892 15790 17186 17157 17476 18517>,
			<16135 16442 17080 16718 16846 18474>,
			<17051 16854 17040 16300 16526 18369>,
			<17582 17067 17075 15893 16470 18097>,
			<17987 17207 17130 15511 16433 17679>,
			<18692 17202 17125 15187 16362 17396>,
			<20164 16936 16967 14873 16180 17211>,
			<21210 16715 16720 14647 15939 17021>,
			<19811 17377 16245 14597 15587 16768>,
			<16678 18802 15558 14654 15193 16457>,
			<15922 19114 15156 14643 15155 16088>,
			<19608 17397 14903 14331 15675 15543>,
			<23137 15798 14772 14063 16112 15187>,
			<22252 17543 15353 14041 15594 15281>,
			<19237 22099 16883 14020 14463 15549>,
			<17588 23783 18215 14293 14186 15780>,
			<17105 22655 19449 17423 15182 15947>,
			<16751 21474 20372 20309 16484 16154>,
			<16436 21498 20726 20349 17574 16670>,
			<16018 21916 20939 20039 18646 17483>,
			<15418 22327 21149 19576 18919 17884>,
			<13998 22788 21428 18327 18162 18018>,
			<12577 23155 21669 17234 17219 18005>,
			<12306 22049 21742 17365 16685 17522>,
			<12237 17781 21711 17915 16235 16567>,
			<12217 15041 21816 18130 16047 16203>,
			<12466 14294 22531 17844 15702 16391>,
			<12834 13802 23354 17532 15408 16623>,
			<12935 13850 23619 17570 15635 16591>,
			<12953 14278 23514 17862 16223 16298>,
			<12981 14570 23088 18330 16893 16273>,
			<13247 14453 21304 19894 17710 17716>,
			<13697 14232 19381 21497 18545 19373>,
			<13967 14225 19054 21439 19169 19632>,
			<14154 14388 19052 20523 19697 19672>,
			<14248 14497 18979 19721 20047 19761>,
			<14049 14497 18324 18866 20348 20781>,
			<13576 14483 17448 17930 20565 22097>,
			<13173 14384 17056 17372 20278 22449>,
			<12776 14044 16846 16976 19273 22296>,
			<12675 13886 16743 16938 18897 20482>,
			<12817 13847 16659 16988 18537 17053>,
			<13001 13806 16156 17185 15669 16529>,
			<13186 14102 17002 17438 17041 16344>,
			<13429 14170 17854 17848 17007 16350>,
			<13675 14813 18780 19439 16990 15840>,
			<13758 16230 19986 18513 16408 15893>,
			<13482 16304 20104 20053 17112 17411>,
			<12291 14850 17292 19563 16927 16772>,
			<10669 13377 14241 22251 20096 18254>,
			<9628 11398 13454 23717 23878 25227>,
			<9628 11398 13454 23717 23878 25227>,
			<9628 11398 13454 23717 23878 25227>;
	};

	qcom,pc-temp-y6-lut {
		qcom,lut-col-legend = <(-10) 0 10 25 40 50>;
		qcom,lut-row-legend = <10000 9800 9600 9400 9200 9000>,
			<8800 8600 8400 8200 8000 7800>,
			<7600 7400 7200 7000 6800 6600>,
			<6400 6200 6000 5800 5600 5400>,
			<5200 5000 4800 4600 4400 4200>,
			<4000 3800 3600 3400 3200 3000>,
			<2800 2600 2400 2200 2000 1800>,
			<1600 1400 1200 1000 900 800>,
			<700 600 500 400 300 200>,
			<100 0>;
		qcom,lut-data = <6075 5475 5190 5027 4990 4980>,
			<6112 5499 5203 5029 4991 4981>,
			<6137 5525 5216 5030 4992 4983>,
			<6152 5548 5227 5031 4993 4984>,
			<6160 5564 5235 5032 4994 4985>,
			<6162 5572 5238 5034 4995 4985>,
			<6151 5569 5236 5035 4996 4986>,
			<6127 5562 5233 5036 4997 4987>,
			<6112 5555 5229 5037 4998 4988>,
			<6104 5545 5225 5038 4999 4988>,
			<6096 5539 5222 5040 5001 4990>,
			<6079 5540 5220 5042 5002 4991>,
			<6058 5544 5219 5045 5004 4992>,
			<6052 5546 5219 5048 5006 4994>,
			<6059 5546 5221 5051 5008 4995>,
			<6066 5546 5224 5055 5011 4997>,
			<6038 5543 5231 5061 5014 5000>,
			<5959 5533 5240 5067 5017 5003>,
			<5908 5519 5241 5071 5022 5007>,
			<5887 5488 5220 5072 5030 5014>,
			<5873 5454 5194 5073 5035 5019>,
			<5858 5436 5177 5063 5027 5012>,
			<5844 5422 5163 5038 5006 4994>,
			<5839 5412 5155 5027 4996 4986>,
			<5842 5406 5152 5025 4993 4984>,
			<5849 5401 5149 5024 4992 4983>,
			<5862 5392 5148 5025 4992 4983>,
			<5891 5380 5148 5027 4994 4984>,
			<5923 5375 5148 5030 4996 4986>,
			<5956 5389 5149 5032 4998 4988>,
			<5992 5417 5151 5034 5001 4990>,
			<6029 5446 5150 5036 5004 4993>,
			<6069 5482 5146 5039 5007 4996>,
			<6109 5522 5144 5041 5009 4998>,
			<6149 5567 5149 5043 5008 4997>,
			<6190 5617 5157 5044 5006 4995>,
			<6226 5672 5168 5042 5003 4993>,
			<6259 5733 5185 5033 4997 4989>,
			<6288 5797 5204 5029 4994 4987>,
			<6313 5861 5223 5030 4995 4988>,
			<6336 5927 5245 5031 4996 4989>,
			<6361 5987 5269 5032 4996 4988>,
			<6388 6041 5298 5033 4994 4985>,
			<6427 6102 5333 5035 4993 4982>,
			<6491 6173 5375 5039 4993 4981>,
			<6585 6242 5422 5055 5004 4998>,
			<6572 6179 5386 5055 5012 5007>,
			<6594 6190 5415 5066 5023 5018>,
			<6710 6259 5443 5075 5031 5021>,
			<6860 6330 5473 5053 5014 4997>,
			<7138 6407 5501 5053 5001 4992>,
			<7903 6535 5550 5062 5004 4994>,
			<9702 6888 5703 5080 5011 4999>,
			<13574 7948 6012 5120 5023 5017>,
			<13574 7948 6012 5120 5023 5017>,
			<13574 7948 6012 5120 5023 5017>;
	};

};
